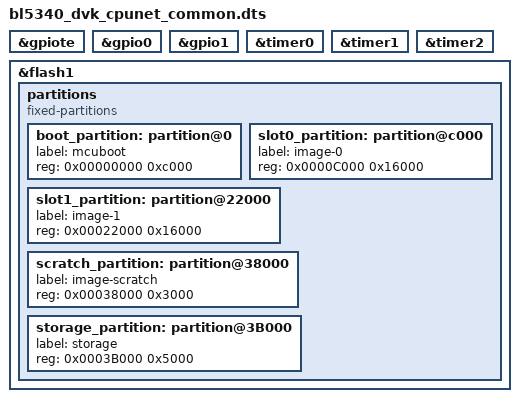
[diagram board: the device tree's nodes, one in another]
/*
 * Copyright (c) 2021-2023 Laird Connectivity
 *
 * SPDX-License-Identifier: Apache-2.0
 */

#include <nordic/nrf5340_cpunet_qkaa.dtsi>

&gpiote {
	status = "okay";
};

&gpio0 {
	status = "okay";
};

&gpio1 {
	status = "okay";
};

&timer0 {
	status = "okay";
};

&timer1 {
	status = "okay";
};

&timer2 {
	status = "okay";
};

&flash1 {
	/*
	 * For more information, see:
	 * http://docs.zephyrproject.org/latest/guides/dts/index.html#flash-partitions
	 */
	partitions {
		compatible = "fixed-partitions";
		#address-cells = <1>;
		#size-cells = <1>;

		/* 48K */
		boot_partition: partition@0 {
			label = "mcuboot";
			reg = <0x00000000 0xc000>;
		};
		/* 88K */
		slot0_partition: partition@c000 {
			label = "image-0";
			reg = <0x0000C000 0x16000>;
		};
		/* 88K */
		slot1_partition: partition@22000 {
			label = "image-1";
			reg = <0x00022000 0x16000>;
		};
		/* 12K */
		scratch_partition: partition@38000 {
			label = "image-scratch";
			reg = <0x00038000 0x3000>;
		};
		/* 20K */
		storage_partition: partition@3B000 {
			label = "storage";
			reg = <0x0003B000 0x5000>;
		};
	};
};

/* Include shared RAM configuration file */
#include "bl5340_dvk_shared_sram_planning_conf.dts"
